VERSION ""

NS_ :

BS_:

BU_: MulticastFID TemporaryTestandMaintenance DataLoading Navigation AirData FlightControls FlightState

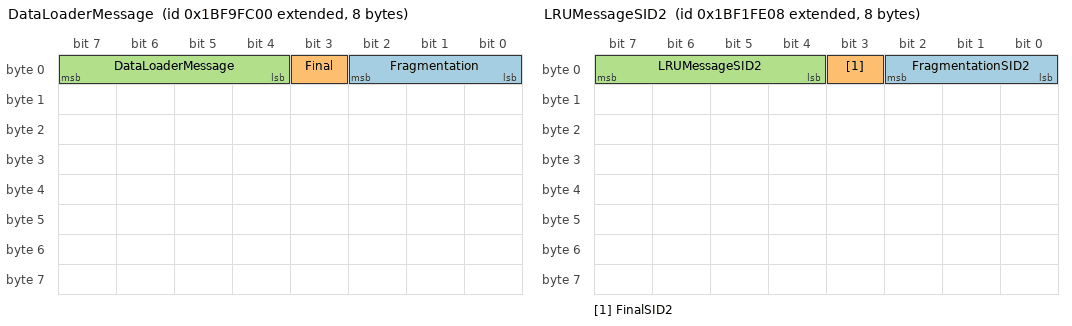
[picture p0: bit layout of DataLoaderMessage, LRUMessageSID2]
BO_ 2616851456 DataLoaderMessage: 8 TemporaryTestandMaintenance
 SG_ Fragmentation : 2|3@0+ (1,0) [0|65535] ""  DataLoading
 SG_ Final : 3|1@0+ (1,0) [0|65535] ""  DataLoading
 SG_ DataLoaderMessage : 7|4@0+ (1,0) [0|65535] ""  DataLoading

BO_ 2616731652 NodeServiceRequestFID20SID1: 8 TemporaryTestandMaintenance
 SG_ NodeServiceRequestFID20SID1 : 7|16@0+ (1,0) [0|65535] ""  Navigation

BO_ 2616731648 NodeServiceRequestFID20SID0: 8 TemporaryTestandMaintenance
 SG_ NodeServiceRequestFID20SID0 : 7|16@0+ (1,0) [0|65535] ""  Navigation

BO_ 2616729604 NodeServiceRequestFID16SID1: 8 TemporaryTestandMaintenance
 SG_ NodeServiceRequestFID16SID1 : 7|16@0+ (1,0) [0|65535] ""  AirData

BO_ 2616729600 NodeServiceRequestFID16SID0: 8 TemporaryTestandMaintenance
 SG_ NodeServiceRequestFID16SID0 : 7|16@0+ (1,0) [0|65535] ""  AirData

BO_ 2616725508 NodeServiceRequestFID8SID1: 8 TemporaryTestandMaintenance
 SG_ NodeServiceRequestFID8SID1 : 7|16@0+ (1,0) [0|65535] ""  FlightControls

BO_ 2616725504 NodeServiceRequestFID8SID0: 8 TemporaryTestandMaintenance
 SG_ NodeServiceRequestFID8SID0 : 7|16@0+ (1,0) [0|65535] ""  FlightControls

BO_ 2616723476 NodeServiceRequestFID4SID5: 8 TemporaryTestandMaintenance
 SG_ NodeServiceRequestFID4SID5 : 7|16@0+ (1,0) [0|65535] ""  FlightState

BO_ 2616723472 NodeServiceRequestFID4SID4: 8 TemporaryTestandMaintenance
 SG_ NodeServiceRequestFID4SID4 : 7|16@0+ (1,0) [0|65535] ""  FlightState

BO_ 2616723468 NodeServiceRequestFID4SID3: 8 TemporaryTestandMaintenance
 SG_ NodeServiceRequestFID4SID3 : 7|16@0+ (1,0) [0|65535] ""  FlightState

BO_ 2616723464 NodeServiceRequestFID4SID2: 8 TemporaryTestandMaintenance
 SG_ NodeServiceRequestFID4SID2 : 7|16@0+ (1,0) [0|65535] ""  FlightState

BO_ 2616723460 NodeServiceRequestFID4SID1: 8 TemporaryTestandMaintenance
 SG_ NodeServiceRequestFID4SID1 : 7|16@0+ (1,0) [0|65535] ""  FlightState

BO_ 2616723456 NodeServiceRequestFID4SID0: 8 TemporaryTestandMaintenance
 SG_ NodeServiceRequestFID4SID0 : 7|16@0+ (1,0) [0|65535] ""  FlightState

BO_ 2616721408 NodeServiceRequestFID0SID0: 8 TemporaryTestandMaintenance
 SG_ NodeServiceRequestFID0SID0 : 7|16@0+ (1,0) [0|65535] ""  MulticastFID

BO_ 2616327688 LRUMessageSID2: 8 DataLoading
 SG_ FragmentationSID2 : 2|3@0+ (1,0) [0|65535] ""  TemporaryTestandMaintenance
 SG_ FinalSID2 : 3|1@0+ (1,0) [0|65535] ""  TemporaryTestandMaintenance
 SG_ LRUMessageSID2 : 7|4@0+ (1,0) [0|65535] ""  TemporaryTestandMaintenance

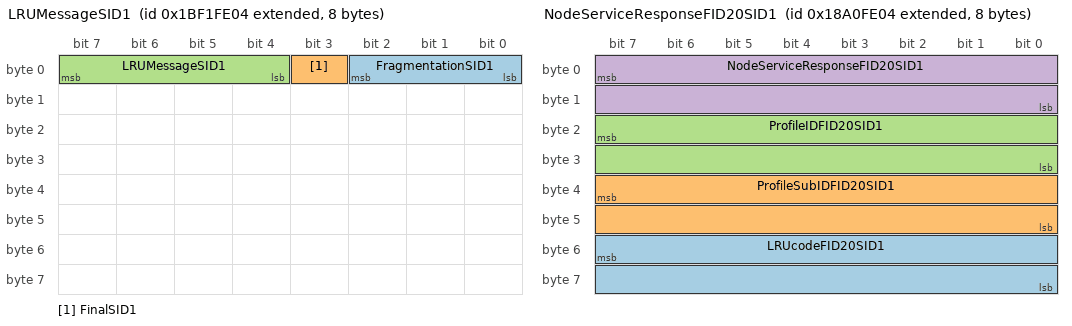
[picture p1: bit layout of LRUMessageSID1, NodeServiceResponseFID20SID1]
BO_ 2616327684 LRUMessageSID1: 8 DataLoading
 SG_ FragmentationSID1 : 2|3@0+ (1,0) [0|65535] ""  TemporaryTestandMaintenance
 SG_ FinalSID1 : 3|1@0+ (1,0) [0|65535] ""  TemporaryTestandMaintenance
 SG_ LRUMessageSID1 : 7|4@0+ (1,0) [0|65535] ""  TemporaryTestandMaintenance

BO_ 2560687620 NodeServiceResponseFID20SID1: 8 Navigation
 SG_ LRUcodeFID20SID1 : 55|16@0+ (1,0) [0|65535] ""  TemporaryTestandMaintenance
 SG_ ProfileSubIDFID20SID1 : 39|16@0+ (1,0) [0|65535] ""  TemporaryTestandMaintenance
 SG_ ProfileIDFID20SID1 : 23|16@0+ (1,0) [0|65535] ""  TemporaryTestandMaintenance
 SG_ NodeServiceResponseFID20SID1 : 7|16@0+ (1,0) [0|0] ""  TemporaryTestandMaintenance

BO_ 2292187216 GPSTimeofWeek: 8 Navigation
 SG_ GPSTimeofWeek : 7|32@0- (1,0) [0|604800] "s"  TemporaryTestandMaintenance,DataLoading,Navigation,AirData,FlightControls,FlightState,MulticastFID

BO_ 2292187208 TrueVerticalVelocity: 8 Navigation
 SG_ TrueVerticalVelocity : 7|32@0- (1,0) [-514|514] "m/s"  TemporaryTestandMaintenance,DataLoading,Navigation,AirData,FlightControls,FlightState,MulticastFID

BO_ 2292187204 TrueNorthVelocity: 8 Navigation
 SG_ TrueNorthVelocity : 7|32@0- (1,0) [-514|514] "m/s"  TemporaryTestandMaintenance,DataLoading,Navigation,AirData,FlightControls,FlightState,MulticastFID

BO_ 2292187200 TrueEastVelocity: 8 Navigation
 SG_ TrueEastVelocity : 7|32@0- (1,0) [-514|514] "m/s"  TemporaryTestandMaintenance,DataLoading,Navigation,AirData,FlightControls,FlightState,MulticastFID

BO_ 2292187148 HeightaboveEllipsoid: 8 Navigation
 SG_ HeightaboveEllipsoid : 7|32@0- (1,0) [-305|18288] "m"  TemporaryTestandMaintenance,DataLoading,Navigation,AirData,FlightControls,FlightState,MulticastFID

BO_ 2292187144 AircraftLongitude: 8 Navigation
 SG_ AircraftLongitude : 7|32@0+ (1,0) [-3.1416|3.1416] "rad"  TemporaryTestandMaintenance,DataLoading,Navigation,AirData,FlightControls,FlightState,MulticastFID

BO_ 2292187140 AircraftLatitude: 8 Navigation
 SG_ AircraftLatitude : 7|32@0+ (1,0) [-1.5708|1.5708] "rad"  TemporaryTestandMaintenance,DataLoading,Navigation,AirData,FlightControls,FlightState,MulticastFID

BO_ 2292187532 INSMode: 8 Navigation
 SG_ INSMode : 7|8@0+ (1,0) [0|255] ""  TemporaryTestandMaintenance,DataLoading,Navigation,AirData,FlightControls,FlightState,MulticastFID

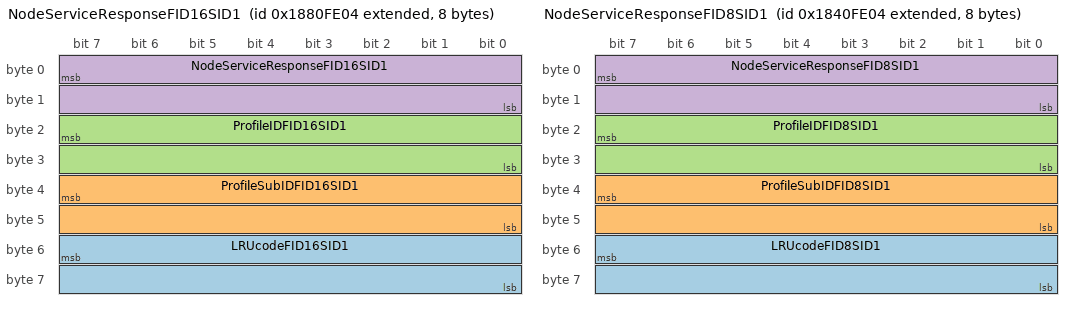
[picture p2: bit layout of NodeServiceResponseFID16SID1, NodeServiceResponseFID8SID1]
BO_ 2558590468 NodeServiceResponseFID16SID1: 8 AirData
 SG_ LRUcodeFID16SID1 : 55|16@0+ (1,0) [0|65535] ""  TemporaryTestandMaintenance
 SG_ ProfileSubIDFID16SID1 : 39|16@0+ (1,0) [0|65535] ""  TemporaryTestandMaintenance
 SG_ ProfileIDFID16SID1 : 23|16@0+ (1,0) [0|65535] ""  TemporaryTestandMaintenance
 SG_ NodeServiceResponseFID16SID1 : 7|16@0+ (1,0) [0|0] ""  TemporaryTestandMaintenance

BO_ 2290090016 StandardAltitude: 8 AirData
 SG_ StandardAltitude : 7|32@0- (1,0) [-305|18288] "m"  TemporaryTestandMaintenance,DataLoading,Navigation,AirData,FlightControls,FlightState,MulticastFID

BO_ 2290089988 IndicatedAirspeed: 8 AirData
 SG_ IndicatedAirspeed : 7|32@0- (1,0) [0|412] "m/s"  TemporaryTestandMaintenance,DataLoading,Navigation,AirData,FlightControls,FlightState,MulticastFID

BO_ 2554396164 NodeServiceResponseFID8SID1: 8 FlightControls
 SG_ LRUcodeFID8SID1 : 55|16@0+ (1,0) [0|65535] ""  TemporaryTestandMaintenance
 SG_ ProfileSubIDFID8SID1 : 39|16@0+ (1,0) [0|65535] ""  TemporaryTestandMaintenance
 SG_ ProfileIDFID8SID1 : 23|16@0+ (1,0) [0|65535] ""  TemporaryTestandMaintenance
 SG_ NodeServiceResponseFID8SID1 : 7|16@0+ (1,0) [0|0] ""  TemporaryTestandMaintenance

BO_ 2286026780 RightAileronPosition: 8 FlightControls
 SG_ RightAileronPosition : 7|32@0- (1,0) [-0.3491|0.3491] "rad"  TemporaryTestandMaintenance,DataLoading,Navigation,AirData,FlightControls,FlightState,MulticastFID

BO_ 2286026776 LeftAileronPosition: 8 FlightControls
 SG_ LeftAileronPosition : 7|32@0- (1,0) [-0.3491|0.3491] "rad"  TemporaryTestandMaintenance,DataLoading,Navigation,AirData,FlightControls,FlightState,MulticastFID

BO_ 2286026772 ElevatorPosition: 8 FlightControls
 SG_ ElevatorPosition : 7|32@0- (1,0) [-0.4363|0.4363] "rad"  TemporaryTestandMaintenance,DataLoading,Navigation,AirData,FlightControls,FlightState,MulticastFID

BO_ 2286026784 RudderPosition: 8 FlightControls
 SG_ RudderPosition : 7|32@0- (1,0) [-0.5236|0.5236] "rad"  TemporaryTestandMaintenance,DataLoading,Navigation,AirData,FlightControls,FlightState,MulticastFID

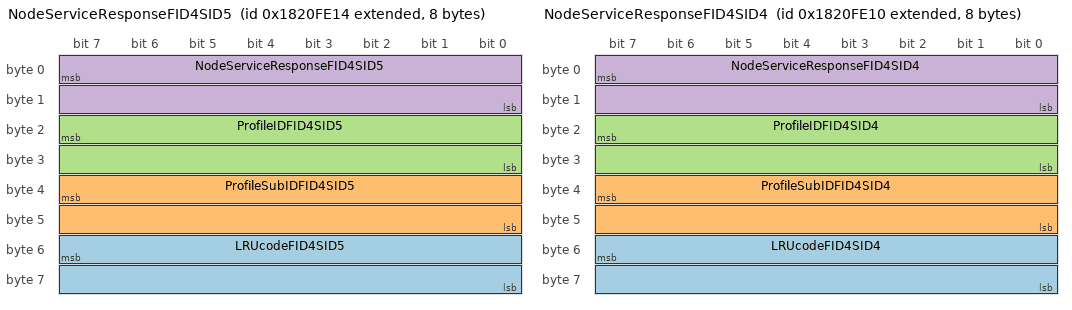
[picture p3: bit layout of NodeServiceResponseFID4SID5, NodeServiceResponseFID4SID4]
BO_ 2552299028 NodeServiceResponseFID4SID5: 8 FlightState
 SG_ LRUcodeFID4SID5 : 55|16@0+ (1,0) [0|65535] ""  TemporaryTestandMaintenance
 SG_ ProfileSubIDFID4SID5 : 39|16@0+ (1,0) [0|65535] ""  TemporaryTestandMaintenance
 SG_ ProfileIDFID4SID5 : 23|16@0+ (1,0) [0|65535] ""  TemporaryTestandMaintenance
 SG_ NodeServiceResponseFID4SID5 : 7|16@0+ (1,0) [0|0] ""  TemporaryTestandMaintenance

BO_ 2552299024 NodeServiceResponseFID4SID4: 8 FlightState
 SG_ LRUcodeFID4SID4 : 55|16@0+ (1,0) [0|65535] ""  TemporaryTestandMaintenance
 SG_ ProfileSubIDFID4SID4 : 39|16@0+ (1,0) [0|65535] ""  TemporaryTestandMaintenance
 SG_ ProfileIDFID4SID4 : 23|16@0+ (1,0) [0|65535] ""  TemporaryTestandMaintenance
 SG_ NodeServiceResponseFID4SID4 : 7|16@0+ (1,0) [0|0] ""  TemporaryTestandMaintenance

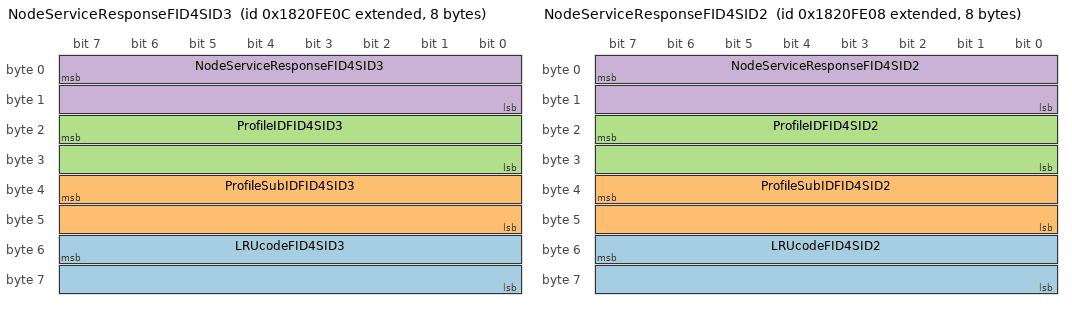
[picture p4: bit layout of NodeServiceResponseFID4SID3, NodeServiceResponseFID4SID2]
BO_ 2552299020 NodeServiceResponseFID4SID3: 8 FlightState
 SG_ LRUcodeFID4SID3 : 55|16@0+ (1,0) [0|65535] ""  TemporaryTestandMaintenance
 SG_ ProfileSubIDFID4SID3 : 39|16@0+ (1,0) [0|65535] ""  TemporaryTestandMaintenance
 SG_ ProfileIDFID4SID3 : 23|16@0+ (1,0) [0|65535] ""  TemporaryTestandMaintenance
 SG_ NodeServiceResponseFID4SID3 : 7|16@0+ (1,0) [0|0] ""  TemporaryTestandMaintenance

BO_ 2552299016 NodeServiceResponseFID4SID2: 8 FlightState
 SG_ LRUcodeFID4SID2 : 55|16@0+ (1,0) [0|65535] ""  TemporaryTestandMaintenance
 SG_ ProfileSubIDFID4SID2 : 39|16@0+ (1,0) [0|65535] ""  TemporaryTestandMaintenance
 SG_ ProfileIDFID4SID2 : 23|16@0+ (1,0) [0|65535] ""  TemporaryTestandMaintenance
 SG_ NodeServiceResponseFID4SID2 : 7|16@0+ (1,0) [0|0] ""  TemporaryTestandMaintenance

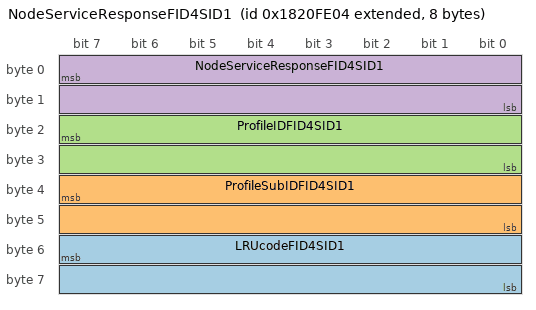
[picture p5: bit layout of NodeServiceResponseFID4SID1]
BO_ 2552299012 NodeServiceResponseFID4SID1: 8 FlightState
 SG_ LRUcodeFID4SID1 : 55|16@0+ (1,0) [0|65535] ""  TemporaryTestandMaintenance
 SG_ ProfileSubIDFID4SID1 : 39|16@0+ (1,0) [0|65535] ""  TemporaryTestandMaintenance
 SG_ ProfileIDFID4SID1 : 23|16@0+ (1,0) [0|65535] ""  TemporaryTestandMaintenance
 SG_ NodeServiceResponseFID4SID1 : 7|16@0+ (1,0) [0|0] ""  TemporaryTestandMaintenance

BO_ 2283798576 BodyYVelocity: 8 FlightState
 SG_ BodyYVelocity : 7|32@0- (1,0) [-514|514] "m/s"  TemporaryTestandMaintenance,DataLoading,Navigation,AirData,FlightControls,FlightState,MulticastFID

BO_ 2283798572 BodyXVelocity: 8 FlightState
 SG_ BodyXVelocity : 7|32@0- (1,0) [-514|514] "m/s"  TemporaryTestandMaintenance,DataLoading,Navigation,AirData,FlightControls,FlightState,MulticastFID

BO_ 2283798568 BodyZVelocity: 8 FlightState
 SG_ BodyZVelocity : 7|32@0- (1,0) [-514|514] "m/s"  TemporaryTestandMaintenance,DataLoading,Navigation,AirData,FlightControls,FlightState,MulticastFID

BO_ 2283798564 HeadingAngle: 8 FlightState
 SG_ HeadingAngle : 7|32@0- (1,0) [-3.1416|3.1416] "rad"  TemporaryTestandMaintenance,DataLoading,Navigation,AirData,FlightControls,FlightState,MulticastFID

BO_ 2283798560 BodyRollAngle: 8 FlightState
 SG_ BodyRollAngle : 7|32@0- (1,0) [-1.5708|1.5708] "rad"  TemporaryTestandMaintenance,DataLoading,Navigation,AirData,FlightControls,FlightState,MulticastFID

BO_ 2283798556 BodyPitchAngle: 8 FlightState
 SG_ BodyPitchAngle : 7|32@0- (1,0) [-1.5708|1.5708] "rad"  TemporaryTestandMaintenance,DataLoading,Navigation,AirData,FlightControls,FlightState,MulticastFID

BO_ 2283798552 BodyYawRate: 8 FlightState
 SG_ BodyYawRate : 7|32@0- (1,0) [-3.49|3.49] "rad/s"  TemporaryTestandMaintenance,DataLoading,Navigation,AirData,FlightControls,FlightState,MulticastFID

BO_ 2283798548 BodyRollRate: 8 FlightState
 SG_ BodyRollRate : 7|32@0- (1,0) [-3.49|3.49] "rad/s"  TemporaryTestandMaintenance,DataLoading,Navigation,AirData,FlightControls,FlightState,MulticastFID

BO_ 2283798544 BodyPitchRate: 8 FlightState
 SG_ BodyPitchRate : 7|32@0- (1,0) [-3.49|3.49] "rad/s"  TemporaryTestandMaintenance,DataLoading,Navigation,AirData,FlightControls,FlightState,MulticastFID

BO_ 2283798540 BodyZAcceleration: 8 FlightState
 SG_ BodyZAcceleration : 7|32@0- (1,0) [-100|100] "m/s2"  TemporaryTestandMaintenance,DataLoading,Navigation,AirData,FlightControls,FlightState,MulticastFID

BO_ 2283798536 BodyYAcceleration: 8 FlightState
 SG_ BodyYAcceleration : 7|32@0- (1,0) [-100|100] "m/s2"  TemporaryTestandMaintenance,DataLoading,Navigation,AirData,FlightControls,FlightState,MulticastFID

BO_ 2283798532 BodyXAcceleration: 8 FlightState
 SG_ BodyXAcceleration : 7|32@0- (1,0) [-100|100] "m/s2"  TemporaryTestandMaintenance,DataLoading,Navigation,AirData,FlightControls,FlightState,MulticastFID

BA_DEF_ SG_  "A825SignalType" ENUM  "noPVS","PVSassigned","PVSvalue";
BA_DEF_ BO_  "A825MsgType" ENUM  "unspecific","PeriodicHealth","HighIntegrity";
BA_DEF_ BU_  "CanEquipment" STRING ;
BA_DEF_ BU_  "NodeLayerModules" STRING ;
BA_DEF_  "DBName" STRING ;
BA_DEF_  "VersionMonth" INT 0 12;
BA_DEF_  "VersionWeek" INT 0 52;
BA_DEF_  "VersionDay" INT 0 31;
BA_DEF_  "ToolVersion" STRING ;
BA_DEF_  "ToolName" STRING ;
BA_DEF_  "TemplateVersion" STRING ;
BA_DEF_  "A825RCIBitSize" INT 0 2;
BA_DEF_  "BusType" STRING ;
BA_DEF_ SG_  "GenSigSendType" ENUM  "Cyclic","OnWrite","OnWriteWithRepetition","OnChange","OnChangeWithRepetition","IfActive","IfActiveWithRepetition","NoSigSendType","NotUsed","NotUsed","NotUsed","NotUsed","NotUsed";
BA_DEF_ BO_  "GenMsgSendType" ENUM  "Cyclic","NotUsed","NotUsed","NotUsed","NotUsed","Cyclic","NotUsed","IfActive","NoMsgSendType","NotUsed";
BA_DEF_ BO_  "GenMsgILSupport" ENUM  "No","Yes";
BA_DEF_ BO_  "GenMsgDelayTime" INT 0 1000;
BA_DEF_ BO_  "GenMsgStartDelayTime" INT 0 65535;
BA_DEF_ BO_  "GenMsgCycleTime" INT 0 50000;
BA_DEF_  "ProtocolType" STRING ;
BA_DEF_DEF_  "A825SignalType" "noPVS";
BA_DEF_DEF_  "A825MsgType" "unspecific";
BA_DEF_DEF_  "CanEquipment" "<unknown>";
BA_DEF_DEF_  "NodeLayerModules" "CANoeILNLVector.dll";
BA_DEF_DEF_  "DBName" "";
BA_DEF_DEF_  "VersionMonth" 1;
BA_DEF_DEF_  "VersionWeek" 1;
BA_DEF_DEF_  "VersionDay" 1;
BA_DEF_DEF_  "ToolVersion" "2.0.0.0";
BA_DEF_DEF_  "ToolName" "manually";
BA_DEF_DEF_  "TemplateVersion" "1.1.0.0";
BA_DEF_DEF_  "A825RCIBitSize" 2;
BA_DEF_DEF_  "BusType" "CAN";
BA_DEF_DEF_  "GenSigSendType" "Cyclic";
BA_DEF_DEF_  "GenMsgSendType" "NoMsgSendType";
BA_DEF_DEF_  "GenMsgILSupport" "Yes";
BA_DEF_DEF_  "GenMsgDelayTime" 0;
BA_DEF_DEF_  "GenMsgStartDelayTime" 0;
BA_DEF_DEF_  "GenMsgCycleTime" 0;
BA_DEF_DEF_  "ProtocolType" "ARINC825V3";
BA_ "DBName" "ARINC825";
BA_ "GenMsgCycleTime" BO_ 2292187216 20;
BA_ "GenMsgCycleTime" BO_ 2292187208 400;
BA_ "GenMsgCycleTime" BO_ 2292187204 400;
BA_ "GenMsgCycleTime" BO_ 2292187200 400;
BA_ "GenMsgCycleTime" BO_ 2292187148 20;
BA_ "GenMsgCycleTime" BO_ 2292187144 20;
BA_ "GenMsgCycleTime" BO_ 2292187140 20;
BA_ "GenMsgCycleTime" BO_ 2292187532 400;
BA_ "GenMsgCycleTime" BO_ 2290090016 20;
BA_ "GenMsgCycleTime" BO_ 2290089988 20;
BA_ "GenMsgSendType" BO_ 2286026780 0;
BA_ "GenMsgCycleTime" BO_ 2286026780 200;
BA_ "GenMsgDelayTime" BO_ 2286026780 50;
BA_ "GenMsgSendType" BO_ 2286026776 0;
BA_ "GenMsgCycleTime" BO_ 2286026776 200;
BA_ "GenMsgDelayTime" BO_ 2286026776 50;
BA_ "GenMsgSendType" BO_ 2286026772 0;
BA_ "GenMsgCycleTime" BO_ 2286026772 200;
BA_ "GenMsgDelayTime" BO_ 2286026772 50;
BA_ "GenMsgCycleTime" BO_ 2283798576 400;
BA_ "GenMsgCycleTime" BO_ 2283798572 400;
BA_ "GenMsgCycleTime" BO_ 2283798568 400;
BA_ "GenMsgCycleTime" BO_ 2283798564 100;
BA_ "GenMsgCycleTime" BO_ 2283798560 200;
BA_ "GenMsgCycleTime" BO_ 2283798556 200;
BA_ "GenMsgCycleTime" BO_ 2283798552 20;
BA_ "GenMsgCycleTime" BO_ 2283798548 200;
BA_ "GenMsgCycleTime" BO_ 2283798544 200;
BA_ "GenMsgCycleTime" BO_ 2283798540 400;
BA_ "GenMsgCycleTime" BO_ 2283798536 400;
BA_ "GenMsgCycleTime" BO_ 2283798532 400;
BA_ "GenSigSendType" SG_ 2616851456 Fragmentation 3;
BA_ "GenSigSendType" SG_ 2616851456 Final 3;
BA_ "GenSigSendType" SG_ 2616851456 DataLoaderMessage 3;
BA_ "GenSigSendType" SG_ 2616731652 NodeServiceRequestFID20SID1 3;
BA_ "GenSigSendType" SG_ 2616731648 NodeServiceRequestFID20SID0 3;
BA_ "GenSigSendType" SG_ 2616729604 NodeServiceRequestFID16SID1 3;
BA_ "GenSigSendType" SG_ 2616729600 NodeServiceRequestFID16SID0 3;
BA_ "GenSigSendType" SG_ 2616725508 NodeServiceRequestFID8SID1 3;
BA_ "GenSigSendType" SG_ 2616725504 NodeServiceRequestFID8SID0 3;
BA_ "GenSigSendType" SG_ 2616723476 NodeServiceRequestFID4SID5 3;
BA_ "GenSigSendType" SG_ 2616723472 NodeServiceRequestFID4SID4 3;
BA_ "GenSigSendType" SG_ 2616723468 NodeServiceRequestFID4SID3 3;
BA_ "GenSigSendType" SG_ 2616723464 NodeServiceRequestFID4SID2 3;
BA_ "GenSigSendType" SG_ 2616723460 NodeServiceRequestFID4SID1 3;
BA_ "GenSigSendType" SG_ 2616723456 NodeServiceRequestFID4SID0 3;
BA_ "GenSigSendType" SG_ 2616721408 NodeServiceRequestFID0SID0 3;
BA_ "GenSigSendType" SG_ 2292187216 GPSTimeofWeek 1.7483819363E-307;
BA_ "GenSigSendType" SG_ 2292187208 TrueVerticalVelocity 1.7483819363E-307;
BA_ "GenSigSendType" SG_ 2292187204 TrueNorthVelocity 1.7483819363E-307;
BA_ "GenSigSendType" SG_ 2292187200 TrueEastVelocity 1.7483819363E-307;
BA_ "GenSigSendType" SG_ 2292187148 HeightaboveEllipsoid 1.7483819363E-307;
BA_ "GenSigSendType" SG_ 2292187144 AircraftLongitude 1.7483819363E-307;
BA_ "GenSigSendType" SG_ 2292187140 AircraftLatitude 1.7483819363E-307;
BA_ "GenSigSendType" SG_ 2292187532 INSMode 1.7483819363E-307;
BA_ "GenSigSendType" SG_ 2290090016 StandardAltitude 1.7483547747E-307;
BA_ "GenSigSendType" SG_ 2290089988 IndicatedAirspeed 1.7483547747E-307;
BA_ "GenSigSendType" SG_ 2554396164 LRUcodeFID8SID1 3;
BA_ "GenSigSendType" SG_ 2554396164 ProfileSubIDFID8SID1 3;
BA_ "GenSigSendType" SG_ 2554396164 ProfileIDFID8SID1 3;
BA_ "GenSigSendType" SG_ 2554396164 NodeServiceResponseFID8SID1 3;
BA_ "GenSigSendType" SG_ 2286026784 RudderPosition 3;
BA_ "GenSigSendType" SG_ 2552299028 LRUcodeFID4SID5 3;
BA_ "GenSigSendType" SG_ 2552299028 ProfileSubIDFID4SID5 3;
BA_ "GenSigSendType" SG_ 2552299028 ProfileIDFID4SID5 3;
BA_ "GenSigSendType" SG_ 2552299028 NodeServiceResponseFID4SID5 3;
BA_ "GenSigSendType" SG_ 2552299024 LRUcodeFID4SID4 3;
BA_ "GenSigSendType" SG_ 2552299024 ProfileSubIDFID4SID4 3;
BA_ "GenSigSendType" SG_ 2552299024 ProfileIDFID4SID4 3;
BA_ "GenSigSendType" SG_ 2552299024 NodeServiceResponseFID4SID4 3;
BA_ "GenSigSendType" SG_ 2552299020 LRUcodeFID4SID3 3;
BA_ "GenSigSendType" SG_ 2552299020 ProfileSubIDFID4SID3 3;
BA_ "GenSigSendType" SG_ 2552299020 ProfileIDFID4SID3 3;
BA_ "GenSigSendType" SG_ 2552299020 NodeServiceResponseFID4SID3 3;
BA_ "GenSigSendType" SG_ 2552299016 LRUcodeFID4SID2 3;
BA_ "GenSigSendType" SG_ 2552299016 ProfileSubIDFID4SID2 3;
BA_ "GenSigSendType" SG_ 2552299016 ProfileIDFID4SID2 3;
BA_ "GenSigSendType" SG_ 2552299016 NodeServiceResponseFID4SID2 3;
BA_ "GenSigSendType" SG_ 2552299012 LRUcodeFID4SID1 3;
BA_ "GenSigSendType" SG_ 2552299012 ProfileSubIDFID4SID1 3;
BA_ "GenSigSendType" SG_ 2552299012 ProfileIDFID4SID1 3;
BA_ "GenSigSendType" SG_ 2552299012 NodeServiceResponseFID4SID1 3;
BA_ "GenSigSendType" SG_ 2283798576 BodyYVelocity 1.7483004516E-307;
BA_ "GenSigSendType" SG_ 2283798572 BodyXVelocity 1.7483004516E-307;
BA_ "GenSigSendType" SG_ 2283798568 BodyZVelocity 1.7483004516E-307;
BA_ "GenSigSendType" SG_ 2283798564 HeadingAngle 1.7483004516E-307;
BA_ "GenSigSendType" SG_ 2283798552 BodyYawRate 1.7483004516E-307;
BA_ "GenSigSendType" SG_ 2283798540 BodyZAcceleration 1.7483004516E-307;
BA_ "GenSigSendType" SG_ 2283798536 BodyYAcceleration 1.7483004516E-307;
BA_ "GenSigSendType" SG_ 2283798532 BodyXAcceleration 1.7483004516E-307;
VAL_ 2616851456 DataLoaderMessage 6 "Download Protocol Initialization Message (DPIM)" 5 "Information Protocol Initialization Message (IPIM)" 4 "File Acknowledgement Message (FILE ACK)" 3 "File Transfer Message (FTM)" 2 "CAN Discovery Response (CDR)" 1 "CAN Discovery Query (CDQ)" ;
VAL_ 2616731652 NodeServiceRequestFID20SID1 6 "Node-ID Setting Service" 5 "Permanent Storage Service" 4 "BIT Control service" 3 "Data Upload Service" 2 "Data Download Service" 1 "Node Synchronization Service" 0 "Node Identification Service" ;
VAL_ 2616731648 NodeServiceRequestFID20SID0 6 "Node-ID Setting Service" 5 "Permanent Storage Service" 4 "BIT Control service" 3 "Data Upload Service" 2 "Data Download Service" 1 "Node Synchronization Service" 0 "Node Identification Service" ;
VAL_ 2616729604 NodeServiceRequestFID16SID1 6 "Node-ID Setting Service" 5 "Permanent Storage Service" 4 "BIT Control service" 3 "Data Upload Service" 2 "Data Download Service" 1 "Node Synchronization Service" 0 "Node Identification Service" ;
VAL_ 2616729600 NodeServiceRequestFID16SID0 6 "Node-ID Setting Service" 5 "Permanent Storage Service" 4 "BIT Control service" 3 "Data Upload Service" 2 "Data Download Service" 1 "Node Synchronization Service" 0 "Node Identification Service" ;
VAL_ 2616725508 NodeServiceRequestFID8SID1 6 "Node-ID Setting Service" 5 "Permanent Storage Service" 4 "BIT Control service" 3 "Data Upload Service" 2 "Data Download Service" 1 "Node Synchronization Service" 0 "Node Identification Service" ;
VAL_ 2616725504 NodeServiceRequestFID8SID0 6 "Node-ID Setting Service" 5 "Permanent Storage Service" 4 "BIT Control service" 3 "Data Upload Service" 2 "Data Download Service" 1 "Node Synchronization Service" 0 "Node Identification Service" ;
VAL_ 2616723476 NodeServiceRequestFID4SID5 6 "Node-ID Setting Service" 5 "Permanent Storage Service" 4 "BIT Control service" 3 "Data Upload Service" 2 "Data Download Service" 1 "Node Synchronization Service" 0 "Node Identification Service" ;
VAL_ 2616723472 NodeServiceRequestFID4SID4 6 "Node-ID Setting Service" 5 "Permanent Storage Service" 4 "BIT Control service" 3 "Data Upload Service" 2 "Data Download Service" 1 "Node Synchronization Service" 0 "Node Identification Service" ;
VAL_ 2616723468 NodeServiceRequestFID4SID3 6 "Node-ID Setting Service" 5 "Permanent Storage Service" 4 "BIT Control service" 3 "Data Upload Service" 2 "Data Download Service" 1 "Node Synchronization Service" 0 "Node Identification Service" ;
VAL_ 2616723464 NodeServiceRequestFID4SID2 6 "Node-ID Setting Service" 5 "Permanent Storage Service" 4 "BIT Control service" 3 "Data Upload Service" 2 "Data Download Service" 1 "Node Synchronization Service" 0 "Node Identification Service" ;
VAL_ 2616723460 NodeServiceRequestFID4SID1 6 "Node-ID Setting Service" 5 "Permanent Storage Service" 4 "BIT Control service" 3 "Data Upload Service" 2 "Data Download Service" 1 "Node Synchronization Service" 0 "Node Identification Service" ;
VAL_ 2616723456 NodeServiceRequestFID4SID0 6 "Node-ID Setting Service" 5 "Permanent Storage Service" 4 "BIT Control service" 3 "Data Upload Service" 2 "Data Download Service" 1 "Node Synchronization Service" 0 "Node Identification Service" ;
VAL_ 2616721408 NodeServiceRequestFID0SID0 6 "Node-ID Setting Service" 5 "Permanent Storage Service" 4 "BIT Control service" 3 "Data Upload Service" 2 "Data Download Service" 1 "Node Synchronization Service" 0 "Node Identification Service" ;
VAL_ 2616327688 LRUMessageSID2 6 "Download Protocol Initialization Message (DPIM)" 5 "Information Protocol Initialization Message (IPIM)" 4 "File Acknowledgement Message (FILE ACK)" 3 "File Transfer Message (FTM)" 2 "CAN Discovery Response (CDR)" 1 "CAN Discovery Query (CDQ)" ;
VAL_ 2616327684 LRUMessageSID1 6 "Download Protocol Initialization Message (DPIM)" 5 "Information Protocol Initialization Message (IPIM)" 4 "File Acknowledgement Message (FILE ACK)" 3 "File Transfer Message (FTM)" 2 "CAN Discovery Response (CDR)" 1 "CAN Discovery Query (CDQ)" ;
VAL_ 2560687620 NodeServiceResponseFID20SID1 6 "Node-ID Setting Service" 5 "Permanent Storage Service" 4 "BIT Control service" 3 "Data Upload Service" 2 "Data Download Service" 1 "Node Synchronization Service" 0 "Node Identification Service" ;
VAL_ 2292187532 INSMode 9 "Attitude in Air Only" 8 "Attitude on Ground Only" 7 "No GPS Ground Alignment" 6 "No GPS Ground" 5 "Full INS Ground" 4 "Dead Reconing Air" 3 "No GPS Air" 2 "Full INS Air" 1 "Alignment" 0 "System initialization" ;
VAL_ 2558590468 NodeServiceResponseFID16SID1 6 "Node-ID Setting Service" 5 "Permanent Storage Service" 4 "BIT Control service" 3 "Data Upload Service" 2 "Data Download Service" 1 "Node Synchronization Service" 0 "Node Identification Service" ;
VAL_ 2554396164 NodeServiceResponseFID8SID1 6 "Node-ID Setting Service" 5 "Permanent Storage Service" 4 "BIT Control service" 3 "Data Upload Service" 2 "Data Download Service" 1 "Node Synchronization Service" 0 "Node Identification Service" ;
VAL_ 2552299028 NodeServiceResponseFID4SID5 6 "Node-ID Setting Service" 5 "Permanent Storage Service" 4 "BIT Control service" 3 "Data Upload Service" 2 "Data Download Service" 1 "Node Synchronization Service" 0 "Node Identification Service" ;
VAL_ 2552299024 NodeServiceResponseFID4SID4 6 "Node-ID Setting Service" 5 "Permanent Storage Service" 4 "BIT Control service" 3 "Data Upload Service" 2 "Data Download Service" 1 "Node Synchronization Service" 0 "Node Identification Service" ;
VAL_ 2552299020 NodeServiceResponseFID4SID3 6 "Node-ID Setting Service" 5 "Permanent Storage Service" 4 "BIT Control service" 3 "Data Upload Service" 2 "Data Download Service" 1 "Node Synchronization Service" 0 "Node Identification Service" ;
VAL_ 2552299016 NodeServiceResponseFID4SID2 6 "Node-ID Setting Service" 5 "Permanent Storage Service" 4 "BIT Control service" 3 "Data Upload Service" 2 "Data Download Service" 1 "Node Synchronization Service" 0 "Node Identification Service" ;
VAL_ 2552299012 NodeServiceResponseFID4SID1 6 "Node-ID Setting Service" 5 "Permanent Storage Service" 4 "BIT Control service" 3 "Data Upload Service" 2 "Data Download Service" 1 "Node Synchronization Service" 0 "Node Identification Service" ;
SIG_VALTYPE_ 2292187208 TrueVerticalVelocity : 1;
SIG_VALTYPE_ 2292187204 TrueNorthVelocity : 1;
SIG_VALTYPE_ 2292187200 TrueEastVelocity : 1;
SIG_VALTYPE_ 2292187148 HeightaboveEllipsoid : 1;
SIG_VALTYPE_ 2290090016 StandardAltitude : 1;
SIG_VALTYPE_ 2290089988 IndicatedAirspeed : 1;
SIG_VALTYPE_ 2286026780 RightAileronPosition : 1;
SIG_VALTYPE_ 2286026776 LeftAileronPosition : 1;
SIG_VALTYPE_ 2286026772 ElevatorPosition : 1;
SIG_VALTYPE_ 2286026784 RudderPosition : 1;
SIG_VALTYPE_ 2283798576 BodyYVelocity : 1;
SIG_VALTYPE_ 2283798572 BodyXVelocity : 1;
SIG_VALTYPE_ 2283798568 BodyZVelocity : 1;
SIG_VALTYPE_ 2283798564 HeadingAngle : 1;
SIG_VALTYPE_ 2283798560 BodyRollAngle : 1;
SIG_VALTYPE_ 2283798556 BodyPitchAngle : 1;
SIG_VALTYPE_ 2283798552 BodyYawRate : 1;
SIG_VALTYPE_ 2283798548 BodyRollRate : 1;
SIG_VALTYPE_ 2283798544 BodyPitchRate : 1;
SIG_VALTYPE_ 2283798540 BodyZAcceleration : 1;
SIG_VALTYPE_ 2283798536 BodyYAcceleration : 1;
SIG_VALTYPE_ 2283798532 BodyXAcceleration : 1;
